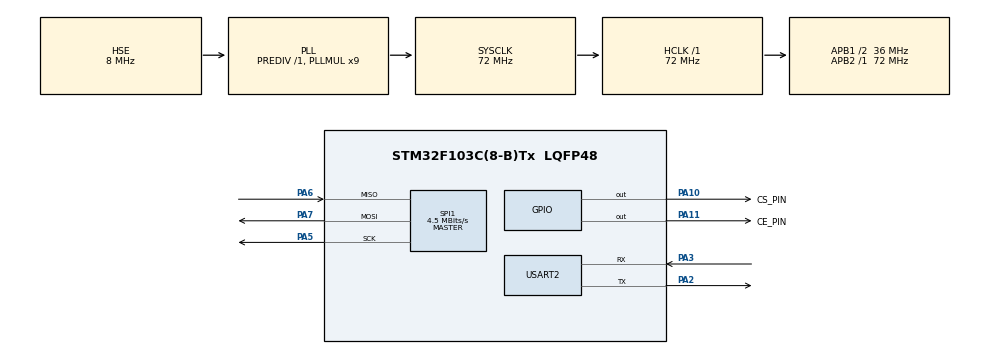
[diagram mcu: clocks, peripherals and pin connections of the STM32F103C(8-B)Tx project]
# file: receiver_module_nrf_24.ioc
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Mcu.Family=STM32F1
RCC.PLLSourceVirtual=RCC_PLLSOURCE_HSE
PA6.Mode=Full_Duplex_Master
PA7.Mode=Full_Duplex_Master
PD1-OSC_OUT.Mode=HSE-External-Oscillator
SPI1.VirtualType=VM_MASTER
PA11.GPIO_Label=CE_PIN
PD0-OSC_IN.Signal=RCC_OSC_IN
RCC.APB1CLKDivider=RCC_HCLK_DIV2
RCC.SYSCLKSource=RCC_SYSCLKSOURCE_PLLCLK
ProjectManager.StackSize=0x400
PD1-OSC_OUT.Signal=RCC_OSC_OUT
PA13.Signal=SYS_JTMS-SWDIO
PA3.Mode=Asynchronous
ProjectManager.TargetToolchain=STM32CubeIDE
SPI1.Direction=SPI_DIRECTION_2LINES
RCC.HCLKFreq_Value=72000000
RCC.APB2TimFreq_Value=72000000
SPI1.CalculateBaudRate=4.5 MBits/s
RCC.USBFreq_Value=72000000
RCC.AHBFreq_Value=72000000
PD0-OSC_IN.Mode=HSE-External-Oscillator
PA5.Signal=SPI1_SCK
board=custom
RCC.PLLMUL=RCC_PLL_MUL9
RCC.APB2Freq_Value=72000000
SPI1.Mode=SPI_MODE_MASTER
PA14.Mode=Serial_Wire
PA10.GPIO_Label=CS_PIN
PA13.Mode=Serial_Wire
Mcu.Name=STM32F103C(8-B)Tx
PA2.Signal=USART2_TX
RCC.SYSCLKFreq_VALUE=72000000
Mcu.Package=LQFP48
PA6.Signal=SPI1_MISO
USART2.VirtualMode=VM_ASYNC
PA11.Signal=GPIO_Output
PA10.Signal=GPIO_Output
PA14.Signal=SYS_JTCK-SWCLK
ProjectManager.HeapSize=0x200
NVIC.PriorityGroup=NVIC_PRIORITYGROUP_4
RCC.APB1TimFreq_Value=72000000
PA2.Mode=Asynchronous
RCC.APB1Freq_Value=36000000
SPI1.BaudRatePrescaler=SPI_BAUDRATEPRESCALER_16
PA3.Signal=USART2_RX
PA5.Mode=Full_Duplex_Master
PA7.Signal=SPI1_MOSI

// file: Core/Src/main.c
/* USER CODE BEGIN Header */
/**
  ******************************************************************************
  * @file           : main.c
  * @brief          : Main program body
  ******************************************************************************
  * @attention
  *
  * <h2><center>&copy; Copyright (c) 2022 STMicroelectronics.
  * All rights reserved.</center></h2>
  *
  * This software component is licensed by ST under BSD 3-Clause license,
  * the "License"; You may not use this file except in compliance with the
  * License. You may obtain a copy of the License at:
  *                        opensource.org/licenses/BSD-3-Clause
  *
  ******************************************************************************
  */
/* USER CODE END Header */
#include "main.h"

/* USER CODE BEGIN Includes */
#include "nrf.h"
#include "string.h"

/* USER CODE END Includes */

SPI_HandleTypeDef hspi1;

UART_HandleTypeDef huart2;

void SystemClock_Config(void);
static void MX_GPIO_Init(void);
static void MX_SPI1_Init(void);
static void MX_USART2_UART_Init(void);

/* USER CODE BEGIN 0 */
uint8_t RxAddress[] = {0x00,0xDD,0xCC,0xBB,0xAA};
uint8_t RxData[32];

uint8_t data[50];
/* USER CODE END 0 */

int main(void)
{

  /* MCU Configuration--------------------------------------------------------*/

  /* Reset of all peripherals, Initializes the Flash interface and the Systick. */
  HAL_Init();

  /* Configure the system clock */
  SystemClock_Config();

  /* Initialize all configured peripherals */
  MX_GPIO_Init();
  MX_SPI1_Init();
  MX_USART2_UART_Init();
  /* USER CODE BEGIN 2 */
//  init_device();
//  nrf_rxmode(RxAddress, 10);
  NRF24_Init();

    NRF24_RxMode(RxAddress, 10);
    NRF24_ReadAll(data);

  /* USER CODE END 2 */

  /* Infinite loop */
  while (1)
  {

    /* USER CODE BEGIN 3 */
	  if (isDataAvailable(2) == 1)
	 	  {
	 		  NRF24_Receive(RxData);
	 		  HAL_UART_Transmit(&huart2, RxData, strlen((char *)RxData), 1000);
	 	  }
  }
  /* USER CODE END 3 */
}

void SystemClock_Config(void)
{
  RCC_OscInitTypeDef RCC_OscInitStruct = {0};
  RCC_ClkInitTypeDef RCC_ClkInitStruct = {0};

  /** Initializes the RCC Oscillators according to the specified parameters
  * in the RCC_OscInitTypeDef structure.
  */
  RCC_OscInitStruct.OscillatorType = RCC_OSCILLATORTYPE_HSE;
  RCC_OscInitStruct.HSEState = RCC_HSE_ON;
  RCC_OscInitStruct.HSEPredivValue = RCC_HSE_PREDIV_DIV1;
  RCC_OscInitStruct.HSIState = RCC_HSI_ON;
  RCC_OscInitStruct.PLL.PLLState = RCC_PLL_ON;
  RCC_OscInitStruct.PLL.PLLSource = RCC_PLLSOURCE_HSE;
  RCC_OscInitStruct.PLL.PLLMUL = RCC_PLL_MUL9;
  if (HAL_RCC_OscConfig(&RCC_OscInitStruct) != HAL_OK)
  {
    Error_Handler();
  }
  /** Initializes the CPU, AHB and APB buses clocks
  */
  RCC_ClkInitStruct.ClockType = RCC_CLOCKTYPE_HCLK|RCC_CLOCKTYPE_SYSCLK
                              |RCC_CLOCKTYPE_PCLK1|RCC_CLOCKTYPE_PCLK2;
  RCC_ClkInitStruct.SYSCLKSource = RCC_SYSCLKSOURCE_PLLCLK;
  RCC_ClkInitStruct.AHBCLKDivider = RCC_SYSCLK_DIV1;
  RCC_ClkInitStruct.APB1CLKDivider = RCC_HCLK_DIV2;
  RCC_ClkInitStruct.APB2CLKDivider = RCC_HCLK_DIV1;

  if (HAL_RCC_ClockConfig(&RCC_ClkInitStruct, FLASH_LATENCY_2) != HAL_OK)
  {
    Error_Handler();
  }
}

static void MX_SPI1_Init(void)
{

  /* SPI1 parameter configuration*/
  hspi1.Instance = SPI1;
  hspi1.Init.Mode = SPI_MODE_MASTER;
  hspi1.Init.Direction = SPI_DIRECTION_2LINES;
  hspi1.Init.DataSize = SPI_DATASIZE_8BIT;
  hspi1.Init.CLKPolarity = SPI_POLARITY_LOW;
  hspi1.Init.CLKPhase = SPI_PHASE_1EDGE;
  hspi1.Init.NSS = SPI_NSS_SOFT;
  hspi1.Init.BaudRatePrescaler = SPI_BAUDRATEPRESCALER_16;
  hspi1.Init.FirstBit = SPI_FIRSTBIT_MSB;
  hspi1.Init.TIMode = SPI_TIMODE_DISABLE;
  hspi1.Init.CRCCalculation = SPI_CRCCALCULATION_DISABLE;
  hspi1.Init.CRCPolynomial = 10;
  if (HAL_SPI_Init(&hspi1) != HAL_OK)
  {
    Error_Handler();
  }

}

static void MX_USART2_UART_Init(void)
{

  huart2.Instance = USART2;
  huart2.Init.BaudRate = 115200;
  huart2.Init.WordLength = UART_WORDLENGTH_8B;
  huart2.Init.StopBits = UART_STOPBITS_1;
  huart2.Init.Parity = UART_PARITY_NONE;
  huart2.Init.Mode = UART_MODE_TX_RX;
  huart2.Init.HwFlowCtl = UART_HWCONTROL_NONE;
  huart2.Init.OverSampling = UART_OVERSAMPLING_16;
  if (HAL_UART_Init(&huart2) != HAL_OK)
  {
    Error_Handler();
  }

}

static void MX_GPIO_Init(void)
{
  GPIO_InitTypeDef GPIO_InitStruct = {0};

  /* GPIO Ports Clock Enable */
  __HAL_RCC_GPIOD_CLK_ENABLE();
  __HAL_RCC_GPIOA_CLK_ENABLE();

  /*Configure GPIO pin Output Level */
  HAL_GPIO_WritePin(GPIOA, CS_PIN_Pin|CE_PIN_Pin, GPIO_PIN_RESET);

  /*Configure GPIO pins : CS_PIN_Pin CE_PIN_Pin */
  GPIO_InitStruct.Pin = CS_PIN_Pin|CE_PIN_Pin;
  GPIO_InitStruct.Mode = GPIO_MODE_OUTPUT_PP;
  GPIO_InitStruct.Pull = GPIO_NOPULL;
  GPIO_InitStruct.Speed = GPIO_SPEED_FREQ_LOW;
  HAL_GPIO_Init(GPIOA, &GPIO_InitStruct);

}

void Error_Handler(void)
{
  /* USER CODE BEGIN Error_Handler_Debug */
  /* User can add his own implementation to report the HAL error return state */
  __disable_irq();
 // while (1)
  //{
  //}
  /* USER CODE END Error_Handler_Debug */
}

/************************ (C) COPYRIGHT STMicroelectronics *****END OF FILE****/
